# STM32F072xB register map
File version: 1.0
Registers are 32-bit, read-write, reset 0x0 unless marked. A register's access mark holds for its fields unless they carry their own. Offsets are from the block's base; lines under a group give offsets from that group; [hi:lo] are bit positions; {n}, {i} and the like mark numbered series; 'fields as' and 'values as' point back to an identical list; <NAME> marks a mode.

## Memory map
0x1FFFF800 OB — Option Bytes Registers
0x40000000 TIM2 — TIM
0x40000400 TIM3 — TIM
0x40001000 TIM6 — TIM
0x40001400 TIM7 — TIM
0x40002000 TIM14 — TIM
0x40002800 RTC — Real-Time Clock
0x40002C00 WWDG — Window WATCHDOG
0x40003000 IWDG — Independent WATCHDOG
0x40003800 SPI2 — Serial Peripheral Interface
0x40004400 USART2 — Universal Synchronous Asynchronous Receiver Transmitter
0x40004800 USART3 — Universal Synchronous Asynchronous Receiver Transmitter
0x40004C00 USART4 — Universal Synchronous Asynchronous Receiver Transmitter
0x40005400 I2C1 — Inter-integrated Circuit Interface
0x40005800 I2C2 — Inter-integrated Circuit Interface
0x40005C00 USB — Universal Serial Bus Full Speed Device
0x40006400 CAN — Controller Area Network
0x40006C00 CRS — Clock Recovery System
0x40007000 PWR — Power Control
0x40007400 DAC — Digital to Analog Converter
0x40007400 DAC1 — Digital to Analog Converter
0x40007800 CEC — HDMI-CEC
0x40010000 SYSCFG — SysTem Configuration
0x4001001C COMP
0x4001001C COMP1 — Comparator
0x4001001C COMP12_COMMON
0x4001001E COMP2 — Comparator
0x40010400 EXTI — External Interrupt/Event Controller
0x40012400 ADC1 — Analog to Digital Converter
0x40012708 ADC
0x40012C00 TIM1 — TIM
0x40013000 SPI1 — Serial Peripheral Interface
0x40013800 USART1 — Universal Synchronous Asynchronous Receiver Transmitter
0x40014000 TIM15 — TIM
0x40014400 TIM16 — TIM
0x40014800 TIM17 — TIM
0x40015800 DBGMCU — Debug MCU
0x40020000 DMA1
0x40021000 RCC — Reset and Clock Control
0x40022000 FLASH — FLASH Registers
0x40023000 CRC — CRC calculation unit
0x40024000 TSC — Touch Sensing Controller (TSC)
0x48000000 GPIOA — General Purpose I/O
0x48000400 GPIOB — General Purpose I/O
0x48000800 GPIOC — General Purpose I/O
0x48000C00 GPIOD — General Purpose I/O
0x48001000 GPIOE — General Purpose I/O
0x48001400 GPIOF — General Purpose I/O

## Interrupts
0 WWDG — Window WatchDog Interrupt
2 RTC — RTC Interrupt through EXTI Lines 17, 19 and 20
3 FLASH — FLASH global Interrupt
4 RCC_CRS (CRS, RCC) — RCC & CRS global Interrupt
5 EXTI0_1 (EXTI) — EXTI Line 0 and 1 Interrupt
6 EXTI2_3 (EXTI) — EXTI Line 2 and 3 Interrupt
7 EXTI4_15 (EXTI) — EXTI Line 4 to 15 Interrupt
8 TSC — Touch Sensing Controller Interrupts
9 DMA1_Channel1 (DMA1) — DMA1 Channel 1 Interrupt
10 DMA1_Channel2_3 (DMA1) — DMA1 Channel 2 and Channel 3 Interrupt
11 DMA1_Channel4_5_6_7 (DMA1) — DMA1 Channel 4 to Channel 7 Interrupt
12 ADC1_COMP (COMP, ADC1) — ADC1 and COMP interrupts (ADC interrupt combined with EXTI Lines 21 and 22
13 TIM1_BRK_UP_TRG_COM (TIM1) — TIM1 Break, Update, Trigger and Commutation Interrupt
14 TIM1_CC (TIM1) — TIM1 Capture Compare Interrupt
15 TIM2 — TIM2 global Interrupt
16 TIM3 — TIM3 global Interrupt
17 TIM6_DAC (TIM6, DAC) — TIM6 global and DAC channel underrun error Interrupt
18 TIM7 — TIM7 global Interrupt
19 TIM14 — TIM14 global Interrupt
20 TIM15 — TIM15 global Interrupt
21 TIM16 — TIM16 global Interrupt
22 TIM17 — TIM17 global Interrupt
23 I2C1 — I2C1 Event Interrupt & EXTI Line23 Interrupt (I2C1 wakeup)
24 I2C2 — I2C2 Event Interrupt
25 SPI1 — SPI1 global Interrupt
26 SPI2 — SPI2 global Interrupt
27 USART1 — USART1 global Interrupt & EXTI Line25 Interrupt (USART1 wakeup)
28 USART2 — USART2 global Interrupt & EXTI Line26 Interrupt (USART2 wakeup)
29 USART3_4 (USART3) — USART3 and USART4 global Interrupt
30 CEC_CAN (CAN, CEC) — CEC and CAN global Interrupts & EXTI Line27 Interrupt
31 USB — USB global Interrupt & EXTI Line18 Interrupt

## OB — Option Bytes Registers
Base 0x1FFFF800
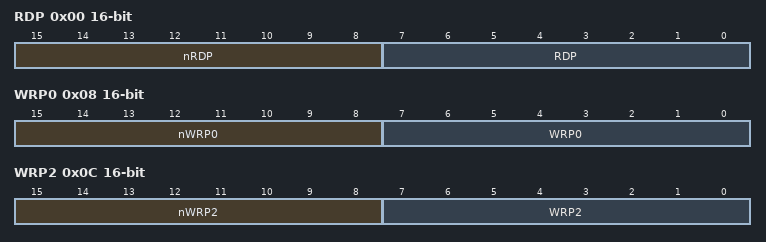
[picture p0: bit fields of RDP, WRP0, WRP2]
0x00 RDP 16-bit — FLASH option byte Read protection
  [15:8] nRDP — Read protection complemented option byte
  [7:0] RDP — Read protection option byte
0x02 USER 16-bit — FLASH option byte user options
  [31:24] nUSER — User complemented option byte
  [23:16] USER — User option byte
0x04 DATA0 16-bit — User data byte 0 (stored in FLASH_OBR[23:16])
0x06 DATA1 16-bit — User data byte 1 (stored in FLASH_OBR[31:24])
0x08 WRP0 16-bit — FLASH option byte write protection 0
  [15:8] nWRP0 — Flash memory write protection complemented option bytes
  [7:0] WRP0 — Flash memory write protection option bytes
0x0A WRP1 16-bit — FLASH option byte write protection 1
  [31:24] nWRP1 — Flash memory write protection complemented option bytes
  [23:16] WRP1 — Flash memory write protection option bytes
0x0C WRP2 16-bit — FLASH option byte write protection 2
  [15:8] nWRP2 — Flash memory write protection complemented option bytes
  [7:0] WRP2 — Flash memory write protection option bytes
0x0E WRP3 16-bit — FLASH option byte write protection 3
  [31:24] nWRP3 — Flash memory write protection complemented option bytes
  [23:16] WRP3 — Flash memory write protection option bytes
